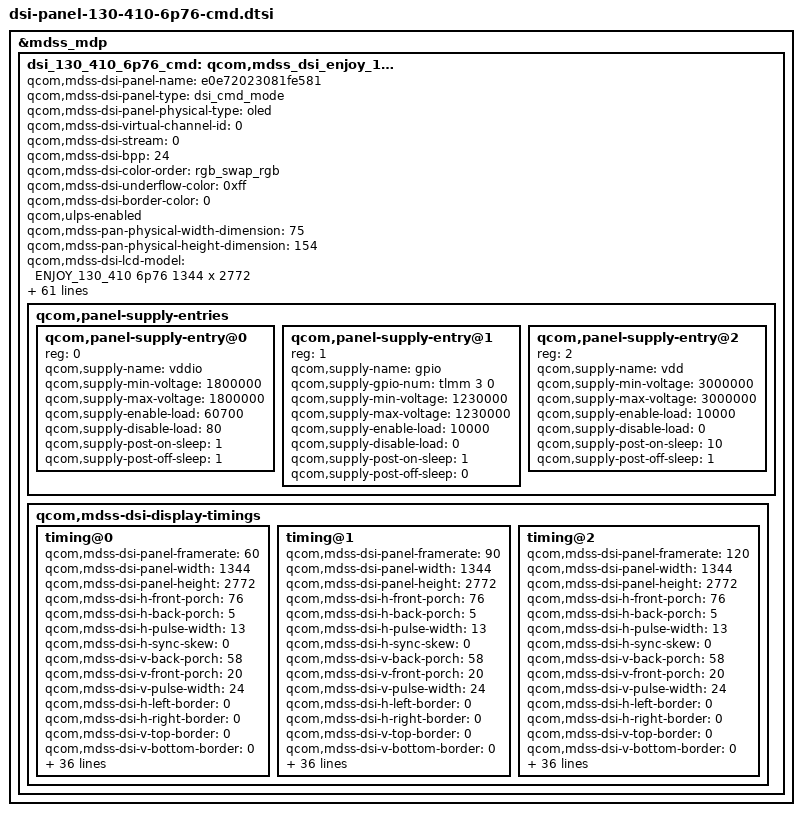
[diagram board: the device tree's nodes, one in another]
&mdss_mdp {
	dsi_130_410_6p76_cmd: qcom,mdss_dsi_enjoy_130_410_6p76_cmd {
		qcom,mdss-dsi-panel-name = "e0e72023081fe581";
		qcom,mdss-dsi-panel-type = "dsi_cmd_mode";
		qcom,mdss-dsi-panel-physical-type = "oled";
		qcom,mdss-dsi-virtual-channel-id = <0>;
		qcom,mdss-dsi-stream = <0>;
		qcom,mdss-dsi-bpp = <24>;
		qcom,mdss-dsi-color-order = "rgb_swap_rgb";
		qcom,mdss-dsi-underflow-color = <0xff>;
		qcom,mdss-dsi-border-color = <0>;
		qcom,ulps-enabled;
		qcom,mdss-pan-physical-width-dimension = <75>;
		qcom,mdss-pan-physical-height-dimension = <154>;
		qcom,mdss-dsi-lcd-model = "ENJOY_130_410 6p76 1344 x 2772";

		/* mipi dsi setting */
		qcom,dsi-ctrl-num = <0>;
		qcom,dsi-phy-num = <0>;
		qcom,dsi-sec-ctrl-num = <1>;
		qcom,dsi-sec-phy-num = <1>;
		qcom,mdss-dsi-traffic-mode = "non_burst_sync_event";
		qcom,mdss-dsi-lane-map = "lane_map_0123";
		qcom,mdss-dsi-bllp-eof-power-mode;
		qcom,mdss-dsi-bllp-power-mode;
		qcom,mdss-dsi-lane-0-state;
		qcom,mdss-dsi-lane-1-state;
		qcom,mdss-dsi-lane-2-state;
		qcom,mdss-dsi-lane-3-state;
		qcom,mdss-dsi-dma-trigger = "trigger_sw";
		qcom,mdss-dsi-mdp-trigger = "none";
		qcom,dsi-select-clocks = "mux_byte_clk0", "mux_pixel_clk0";
		qcom,dsi-select-sec-clocks = "mux_byte_clk1", "mux_pixel_clk1";

		/* TE setting */
		qcom,mdss-dsi-te-pin-select = <1>;
		qcom,mdss-dsi-wr-mem-start = <0x2c>;
		qcom,mdss-dsi-wr-mem-continue = <0x3c>;
		qcom,mdss-dsi-te-dcs-command = <1>;
		qcom,mdss-dsi-te-check-enable;
		qcom,mdss-dsi-te-using-te-pin;

		/* hdr setting */
		qcom,mdss-dsi-panel-hdr-enabled;
		qcom,mdss-dsi-panel-hdr-color-primaries = <14500 15500 32000
			17000 15500 30000 8000 3000>;
		qcom,mdss-dsi-panel-peak-brightness = <4200000>;
		qcom,mdss-dsi-panel-blackness-level = <3230>;

		/* hbm enable */
		qcom,mdss-dsi-panel-hbm-enabled;

		/* gpio setting */
		qcom,dsi-panel-gpio-address = <0x0F100000 0x1000>;
		qcom,dsi-panel-gpio-pins = <24 3>;
		qcom,dsi-panel-gpio-names = "reset-gpio", "vdd-gpio";

		/* esd check setting */
		qcom,mdss-dsi-panel-status-check-mode = "reg_read";
		qcom,mdss-dsi-panel-status-command = [06 01 00 01 00 00 01 0a];
		qcom,mdss-dsi-panel-status-command-state = "dsi_lp_mode";
		qcom,mdss-dsi-panel-status-value = <0x9c>;
		qcom,mdss-dsi-panel-status-read-length = <1>;
		qcom,esd-check-enabled;

		/* check reg */
		qcom,mdss-dsi-panel-lcd-check-reg-enabled;
		qcom,mdss-dsi-panel-lcd-check-reg-expect_vals = <0x9c>;

		/* oem info */
		qcom,mdss-dsi-panel-oem-info-enabled;
		qcom,mdss-dsi-panel-oem-2d-barcode-enabled;
		qcom,mdss-dsi-panel-oem-sn-enabled;

		/* backlight setting */
		qcom,mdss-dsi-bl-pmic-control-type = "bl_ctrl_dcs";
		qcom,mdss-dsi-bl-min-level = <1>;
		qcom,mdss-dsi-bl-max-level = <4095>;
		qcom,mdss-brightness-max-level = <4095>;
		qcom,mdss-dsi-bl-inverted-dbv;
		qcom,mdss-dsi-bl-max-nit = <1000>;

		/* dfps setting */
		qcom,dsi-fps-list = <60 90 120>;

		/* power on/off timing setting */
		qcom,platform-reset-gpio = <&tlmm 24 0>;
		qcom,mdss-dsi-reset-sequence = <1 1>, <0 1>, <1 10>;
		qcom,mdss-dsi-panel-reset-in-lp11;
		qcom,panel-supply-entries {
			qcom,panel-supply-entry@0 {
					reg = <0>;
					qcom,supply-name = "vddio";
					qcom,supply-min-voltage = <1800000>;
					qcom,supply-max-voltage = <1800000>;
					qcom,supply-enable-load = <60700>;
					qcom,supply-disable-load = <80>;
					qcom,supply-post-on-sleep = <1>;
					qcom,supply-post-off-sleep = <1>;
			};
			qcom,panel-supply-entry@1 {
					reg = <1>;
					qcom,supply-name = "gpio";
					qcom,supply-gpio-num = <&tlmm 3 0>;
					qcom,supply-min-voltage = <1230000>;
					qcom,supply-max-voltage = <1230000>;
					qcom,supply-enable-load = <10000>;
					qcom,supply-disable-load = <0>;
					qcom,supply-post-on-sleep = <1>;
					qcom,supply-post-off-sleep = <0>;
			};
			qcom,panel-supply-entry@2 {
					reg = <2>;
					qcom,supply-name = "vdd";
					qcom,supply-min-voltage = <3000000>;
					qcom,supply-max-voltage = <3000000>;
					qcom,supply-enable-load = <10000>;
					qcom,supply-disable-load = <0>;
					qcom,supply-post-on-sleep = <10>;
					qcom,supply-post-off-sleep = <1>;
			};
		};
		/* display timing0 */
		qcom,mdss-dsi-display-timings {
			timing@0 {
				qcom,mdss-dsi-panel-framerate = <60>;
				qcom,mdss-dsi-panel-width = <1344>;
				qcom,mdss-dsi-panel-height = <2772>;
				qcom,mdss-dsi-h-front-porch = <76>;
				qcom,mdss-dsi-h-back-porch = <5>;
				qcom,mdss-dsi-h-pulse-width = <13>;
				qcom,mdss-dsi-h-sync-skew = <0>;
				qcom,mdss-dsi-v-back-porch = <58>;
				qcom,mdss-dsi-v-front-porch = <20>;
				qcom,mdss-dsi-v-pulse-width = <24>;
				qcom,mdss-dsi-h-left-border = <0>;
				qcom,mdss-dsi-h-right-border = <0>;
				qcom,mdss-dsi-v-top-border = <0>;
				qcom,mdss-dsi-v-bottom-border = <0>;
				qcom,mdss-dsi-panel-jitter = <0x4 0x1>;

				qcom,mdss-dsi-on-command = [
					15 01 00 00 00 00 02 fe d2
					15 01 00 00 00 00 02 4f 08
					15 01 00 00 00 00 02 fe d2
					15 01 00 00 00 00 02 50 11
					15 01 00 00 00 00 02 51 89
					15 01 00 00 00 00 02 fe 00
					15 01 00 00 00 00 02 c2 08
					15 01 00 00 00 00 02 35 00
					39 01 00 00 00 00 03 51 0d bb
					05 01 00 00 46 00 01 11
					05 01 00 00 4f 00 01 29
				];

				qcom,mdss-dsi-off-command = [
					05 01 00 00 00 00 01 28
					05 01 00 00 78 00 01 10
				];

				qcom,mdss-dsi-fp-hbm-enable-commands = [
					39 01 00 00 00 00 03 51 0F FF
				];

				qcom,mdss-dsi-timing-switch-command = [
					15 01 00 00 00 00 02 FE 40
					15 01 00 00 09 00 02 BD 00
					15 01 00 00 00 00 02 FE 00
				];

				qcom,mdss-dsi-lp1-command = [
					15 00 00 00 00 00 02 FE 00
					05 01 00 00 00 00 01 39
				];

				qcom,mdss-dsi-nolp-command = [
					15 00 00 00 00 00 02 FE 00
					05 01 00 00 00 00 01 38
				];

				qcom,mdss-dsi-panel-lcd-check-reg-commands = [
					06 01 00 01 00 00 01 0a
				];

				qcom,mdss-dsi-oeminfo-read-commands = [
					15 01 00 00 00 00 02 FE C2
					06 01 00 01 00 00 01 00
					06 01 00 01 00 00 01 01
					06 01 00 01 00 00 01 02
					06 01 00 01 00 00 01 03
					06 01 00 01 00 00 01 04
					06 01 00 01 00 00 01 05
					06 01 00 01 00 00 01 06
					06 01 00 01 00 00 01 07
					06 01 00 01 00 00 01 08
					06 01 00 01 00 00 01 09
					06 01 00 01 00 00 01 0A
					06 01 00 01 00 00 01 0B
					06 01 00 01 00 00 01 0C
					06 01 00 01 00 00 01 0D
					06 01 00 01 00 00 01 0E
					06 01 00 01 00 00 01 0F
					06 01 00 01 00 00 01 10
					06 01 00 01 00 00 01 11
					06 01 00 01 00 00 01 12
					06 01 00 01 00 00 01 13
					06 01 00 01 00 00 01 14
				];

				qcom,mdss-dsi-on-command-state = "dsi_lp_mode";
				qcom,mdss-dsi-off-command-state = "dsi_hs_mode";
				qcom,mdss-dsi-panel-lcd-check-reg-commands-state =
					"dsi_lp_mode";
				qcom,mdss-dsi-oeminfo-read-commands-state =
					"dsi_lp_mode";

				qcom,mdss-dsi-h-sync-pulse = <0>;
				qcom,compression-mode = "dsc";
				qcom,mdss-dsc-version = <0x12>;
				qcom,mdss-dsc-slice-height = <44>;
				qcom,mdss-dsc-slice-width = <672>;
				qcom,mdss-dsc-slice-per-pkt = <2>;
				qcom,mdss-dsc-bit-per-component = <10>;
				qcom,mdss-dsc-bit-per-pixel = <8>;
				qcom,mdss-dsc-block-prediction-enable;
				qcom,mdss-dsi-panel-phy-timings = [00 14 05 05 13 1f 05
						05 05 06 02 04 12 0a];
				qcom,display-topology = <2 2 1>;
				qcom,default-topology-index = <0>;
			};
			timing@1 {
				qcom,mdss-dsi-panel-framerate = <90>;
				qcom,mdss-dsi-panel-width = <1344>;
				qcom,mdss-dsi-panel-height = <2772>;
				qcom,mdss-dsi-h-front-porch = <76>;
				qcom,mdss-dsi-h-back-porch = <5>;
				qcom,mdss-dsi-h-pulse-width = <13>;
				qcom,mdss-dsi-h-sync-skew = <0>;
				qcom,mdss-dsi-v-back-porch = <58>;
				qcom,mdss-dsi-v-front-porch = <20>;
				qcom,mdss-dsi-v-pulse-width = <24>;
				qcom,mdss-dsi-h-left-border = <0>;
				qcom,mdss-dsi-h-right-border = <0>;
				qcom,mdss-dsi-v-top-border = <0>;
				qcom,mdss-dsi-v-bottom-border = <0>;
				qcom,mdss-dsi-panel-jitter = <0x4 0x1>;

				qcom,mdss-dsi-on-command = [
					15 01 00 00 00 00 02 fe d2
					15 01 00 00 00 00 02 4f 08
					15 01 00 00 00 00 02 fe d2
					15 01 00 00 00 00 02 fe 00
					15 01 00 00 00 00 02 fa 01
					15 01 00 00 00 00 02 fe 00
					15 01 00 00 00 00 02 c2 08
					15 01 00 00 00 00 02 35 00
					39 01 00 00 00 00 03 51 0d bb
					05 01 00 00 46 00 01 11
					05 01 00 00 4f 00 01 29
				];

				qcom,mdss-dsi-off-command = [
					05 01 00 00 00 00 01 28
					05 01 00 00 78 00 01 10
				];

				qcom,mdss-dsi-fp-hbm-enable-commands = [
					39 01 00 00 00 00 03 51 0F FF
				];

				qcom,mdss-dsi-timing-switch-command = [
					15 01 00 00 00 00 02 FE 40
					15 01 00 00 00 00 02 BD 05
					15 01 00 00 00 00 02 FE 00
				];

				qcom,mdss-dsi-lp1-command = [
					15 00 00 00 00 00 02 FE 00
					05 01 00 00 00 00 01 39
				];

				qcom,mdss-dsi-nolp-command = [
					15 00 00 00 00 00 02 FE 00
					05 01 00 00 00 00 01 38
				];

				qcom,mdss-dsi-panel-lcd-check-reg-commands = [
					06 01 00 01 00 00 01 0a
				];

				qcom,mdss-dsi-oeminfo-read-commands = [
					15 01 00 00 00 00 02 FE C2
					06 01 00 01 00 00 01 00
					06 01 00 01 00 00 01 01
					06 01 00 01 00 00 01 02
					06 01 00 01 00 00 01 03
					06 01 00 01 00 00 01 04
					06 01 00 01 00 00 01 05
					06 01 00 01 00 00 01 06
					06 01 00 01 00 00 01 07
					06 01 00 01 00 00 01 08
					06 01 00 01 00 00 01 09
					06 01 00 01 00 00 01 0A
					06 01 00 01 00 00 01 0B
					06 01 00 01 00 00 01 0C
					06 01 00 01 00 00 01 0D
					06 01 00 01 00 00 01 0E
					06 01 00 01 00 00 01 0F
					06 01 00 01 00 00 01 10
					06 01 00 01 00 00 01 11
					06 01 00 01 00 00 01 12
					06 01 00 01 00 00 01 13
					06 01 00 01 00 00 01 14
				];

				qcom,mdss-dsi-on-command-state = "dsi_lp_mode";
				qcom,mdss-dsi-off-command-state = "dsi_hs_mode";
				qcom,mdss-dsi-panel-lcd-check-reg-commands-state =
					"dsi_lp_mode";
				qcom,mdss-dsi-oeminfo-read-commands-state =
					"dsi_lp_mode";

				qcom,mdss-dsi-h-sync-pulse = <0>;
				qcom,compression-mode = "dsc";
				qcom,mdss-dsc-version = <0x12>;
				qcom,mdss-dsc-slice-height = <44>;
				qcom,mdss-dsc-slice-width = <672>;
				qcom,mdss-dsc-slice-per-pkt = <2>;
				qcom,mdss-dsc-bit-per-component = <10>;
				qcom,mdss-dsc-bit-per-pixel = <8>;
				qcom,mdss-dsc-block-prediction-enable;
				qcom,mdss-dsi-panel-phy-timings = [00 1d 07 07 17 22 07
					07 07 08 02 04 19 0c];
				qcom,display-topology = <2 2 1>;
				qcom,default-topology-index = <0>;
			};
			timing@2 {
				qcom,mdss-dsi-panel-framerate = <120>;
				qcom,mdss-dsi-panel-width = <1344>;
				qcom,mdss-dsi-panel-height = <2772>;
				qcom,mdss-dsi-h-front-porch = <76>;
				qcom,mdss-dsi-h-back-porch = <5>;
				qcom,mdss-dsi-h-pulse-width = <13>;
				qcom,mdss-dsi-h-sync-skew = <0>;
				qcom,mdss-dsi-v-back-porch = <58>;
				qcom,mdss-dsi-v-front-porch = <20>;
				qcom,mdss-dsi-v-pulse-width = <24>;
				qcom,mdss-dsi-h-left-border = <0>;
				qcom,mdss-dsi-h-right-border = <0>;
				qcom,mdss-dsi-v-top-border = <0>;
				qcom,mdss-dsi-v-bottom-border = <0>;
				qcom,mdss-dsi-panel-jitter = <0x4 0x1>;

				qcom,mdss-dsi-on-command = [
					15 01 00 00 00 00 02 fe d2
					15 01 00 00 00 00 02 4f 08
					15 01 00 00 00 00 02 fe d2
					15 01 00 00 00 00 02 fe 00
					15 01 00 00 00 00 02 fa 01
					15 01 00 00 00 00 02 fe 00
					15 01 00 00 00 00 02 c2 08
					15 01 00 00 00 00 02 35 00
					39 01 00 00 00 00 03 51 0d bb
					05 01 00 00 46 00 01 11
					05 01 00 00 4f 00 01 29
				];

				qcom,mdss-dsi-off-command = [
					05 01 00 00 00 00 01 28
					05 01 00 00 78 00 01 10
				];

				qcom,mdss-dsi-fp-hbm-enable-commands = [
					39 01 00 00 00 00 03 51 0F FF
				];

				qcom,mdss-dsi-timing-switch-command = [
					15 01 00 00 00 00 02 FE 40
					15 01 00 00 00 00 02 BD 05
					15 01 00 00 00 00 02 FE 00
				];

				qcom,mdss-dsi-lp1-command = [
					15 00 00 00 00 00 02 FE 00
					05 01 00 00 00 00 01 39
				];

				qcom,mdss-dsi-nolp-command = [
					15 00 00 00 00 00 02 FE 00
					05 01 00 00 00 00 01 38
				];

				qcom,mdss-dsi-panel-lcd-check-reg-commands = [
					06 01 00 01 00 00 01 0a
				];

				qcom,mdss-dsi-oeminfo-read-commands = [
					15 01 00 00 00 00 02 FE C2
					06 01 00 01 00 00 01 00
					06 01 00 01 00 00 01 01
					06 01 00 01 00 00 01 02
					06 01 00 01 00 00 01 03
					06 01 00 01 00 00 01 04
					06 01 00 01 00 00 01 05
					06 01 00 01 00 00 01 06
					06 01 00 01 00 00 01 07
					06 01 00 01 00 00 01 08
					06 01 00 01 00 00 01 09
					06 01 00 01 00 00 01 0A
					06 01 00 01 00 00 01 0B
					06 01 00 01 00 00 01 0C
					06 01 00 01 00 00 01 0D
					06 01 00 01 00 00 01 0E
					06 01 00 01 00 00 01 0F
					06 01 00 01 00 00 01 10
					06 01 00 01 00 00 01 11
					06 01 00 01 00 00 01 12
					06 01 00 01 00 00 01 13
					06 01 00 01 00 00 01 14
				];

				qcom,mdss-dsi-on-command-state = "dsi_lp_mode";
				qcom,mdss-dsi-off-command-state = "dsi_hs_mode";
				qcom,mdss-dsi-panel-lcd-check-reg-commands-state =
					"dsi_lp_mode";
				qcom,mdss-dsi-oeminfo-read-commands-state =
					"dsi_lp_mode";

				qcom,mdss-dsi-h-sync-pulse = <0>;
				qcom,compression-mode = "dsc";
				qcom,mdss-dsc-version = <0x12>;
				qcom,mdss-dsc-slice-height = <44>;
				qcom,mdss-dsc-slice-width = <672>;
				qcom,mdss-dsc-slice-per-pkt = <2>;
				qcom,mdss-dsc-bit-per-component = <10>;
				qcom,mdss-dsc-bit-per-pixel = <8>;
				qcom,mdss-dsc-block-prediction-enable;
				qcom,mdss-dsi-panel-phy-timings = [00 25 0a 0a 1b 18 0a
					0a 0a 0a 02 04 1f 0f];
				qcom,display-topology = <2 2 1>;
				qcom,default-topology-index = <0>;
			};
		};
	};
};
